AUTOSAR XML (schema 00051)
standard types defined: uint16, uint32
package /Components
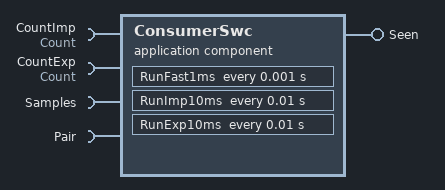
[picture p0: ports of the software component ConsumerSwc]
  application sw component type ConsumerSwc
    4 x require port:
      CountImp: nonqueued-receiver-com-spec{data-element=Count, init-value=0}, required-interface=Count
      CountExp: nonqueued-receiver-com-spec{data-element=Count, init-value=0}, required-interface=Count
      Samples: nonqueued-receiver-com-spec{data-element=Samples, init-value=[0, 0, 0]}, required-interface=Samples
      Pair: nonqueued-receiver-com-spec{data-element=Pair, init-value=fields=[0, 0]}, required-interface=Pair
    provide port Seen: nonqueued-sender-com-spec{data-element=Seen, init-value=0}, provided-interface=Seen
    behavior ConsumerSwc_IB: handle-termination-and-restart=NO-SUPPORT
      timing event Event_RunFast1ms: start-on-event=RunFast1ms, period=0.001
      timing event Event_RunImp10ms: start-on-event=RunImp10ms, period=0.01
      timing event Event_RunExp10ms: start-on-event=RunExp10ms, period=0.01
      runnable RunFast1ms
        data-read-access:
          access IRead_CountImp_Count: accessed-variable=CountImp.Count
        data-receive-point-by-arguments:
          access IN_CountExp_Count: accessed-variable=CountExp.Count
      runnable RunImp10ms
        data-read-access:
          access IRead_CountImp_Count: accessed-variable=CountImp.Count
          access IRead_Samples_Samples: accessed-variable=Samples.Samples
          access IRead_Pair_Pair: accessed-variable=Pair.Pair
        data-write-access:
          access IWrite_Seen_Seen: accessed-variable=Seen.Seen
      runnable RunExp10ms
        data-receive-point-by-arguments:
          access IN_CountExp_Count: accessed-variable=CountExp.Count
package /Interfaces
  4 x sender receiver interface:
    Count
      data Count: type=uint32
    Samples
      data Samples: type=ImpSamples
    Pair
      data Pair: type=ImpPair
    Seen
      data Seen: type=uint32
package /DataTypes
  impl type ImpSamples: category=ARRAY
    element ImpSamples: array-size=3, array-size-semantics=FIXED-SIZE, implementation-data-type=uint16
  impl type ImpPair: category=STRUCTURE
    element A: implementation-data-type=uint32
    element B: implementation-data-type=uint32
